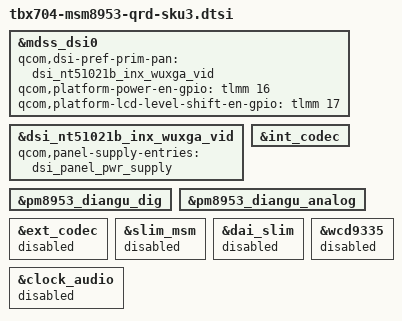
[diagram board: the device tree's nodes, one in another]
/*
 * Copyright (c) 2015-2016, The Linux Foundation. All rights reserved.
 *
 * This program is free software; you can redistribute it and/or modify
 * it under the terms of the GNU General Public License version 2 and
 * only version 2 as published by the Free Software Foundation.
 *
 * This program is distributed in the hope that it will be useful,
 * but WITHOUT ANY WARRANTY; without even the implied warranty of
 * MERCHANTABILITY or FITNESS FOR A PARTICULAR PURPOSE.  See the
 * GNU General Public License for more details.
 */

&mdss_dsi0 {
	/delete-property/ lab-supply;
	/delete-property/ ibb-supply;

	qcom,dsi-pref-prim-pan = <&dsi_nt51021b_inx_wuxga_vid>;
	qcom,platform-power-en-gpio = <&tlmm 16 0>;
	qcom,platform-lcd-level-shift-en-gpio = <&tlmm 17 0>;
};


/* Add-Begin by Phoenix.Wu for Achillies4 Plus LCD */
&dsi_nt51021b_inx_wuxga_vid {
	qcom,panel-supply-entries = <&dsi_panel_pwr_supply>;
};
/* Add-end by Phoenix.Wu for Achillies4 Plus LCD */

&int_codec {
	status = "ok";
};

&pm8953_diangu_dig {
	status = "ok";
};

&pm8953_diangu_analog {
	status = "ok";
};

&ext_codec {
	status = "disabled";
};

&slim_msm {
	status = "disabled";
};

&dai_slim {
	status = "disabled";
};

&clock_audio {
	status = "disabled";
};

&wcd9335 {
	status = "disabled";
};
